# iND83213A register map
Vendor: Indiemicro; Series: Rugby; File version: 1.0
CPU: CM0 r0p1, selectable endian, no MPU, no FPU, 4 interrupt priority bits
Registers are 32-bit, read-write, no defined reset value unless marked. A register's access mark holds for its fields unless they carry their own. Offsets are from the block's base; [hi:lo] are bit positions.

## PMUAPRE5V — Power Management Unit of 5V domain
Base 0x50015000; register names take the prefix PMUAPRE5V_
0x00 RETAIN0 — Retained data 0
  [7:0] RETAIN0 — Firmware scratch register 0. Only reset at power-on (e.g contents retained in Hibernate mode and retained despite any hard or soft resets)
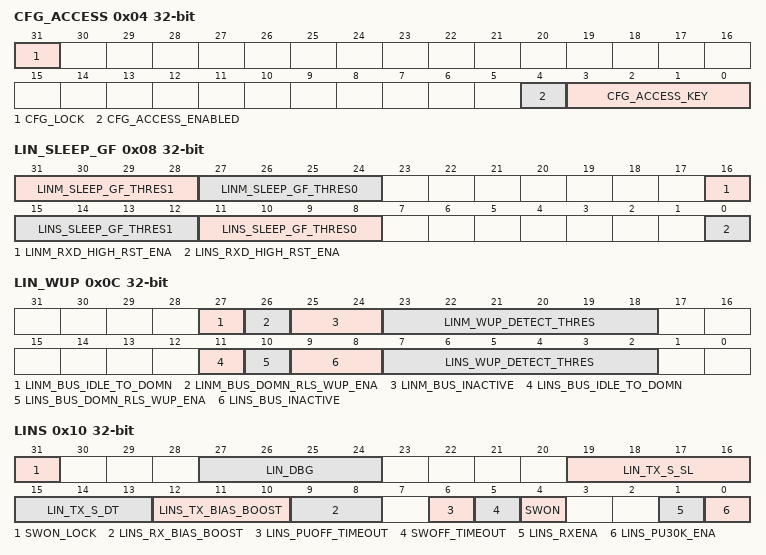
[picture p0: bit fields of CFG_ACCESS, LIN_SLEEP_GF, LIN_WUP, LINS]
0x04 CFG_ACCESS — 5V domain's configuration regs access
  [31] CFG_LOCK — Set Only bit. Write 1 to this bit to lock CFG_CODE bits.
  [4] CFG_ACCESS_ENABLED ro — A status flag that is set when 5V domain's configuration regs access is enabled
  [3:0] CFG_ACCESS_KEY — Write the value 0xB to this register to enable 'trim access' (which allows write access to various trim settings and production test options). Write any other value to disable trim access.
0x08 LIN_SLEEP_GF — LINS Glitch Filter Configuration in active mode.
  [31:28] LINM_SLEEP_GF_THRES1 — LINM RXD glitch filter threshold for 0 to 1, detect '1' width of (T_clk_lf*resetvalue = 4us*3 = 12[us]
  [27:24] LINM_SLEEP_GF_THRES0 — LINM RXD glitch filter threshold for 1 to 0, detect '0' width of (T_clk_lf*resetvalue = 4us*3 = 12[us]
  [16] LINM_RXD_HIGH_RST_ENA — Enable signal that LINs RXD glitch filter at sleep mode is asynchronous reset by high of LINs_RXD.
  [15:12] LINS_SLEEP_GF_THRES1 — LINS RXD glitch filter threshold for 0 to 1, detect '1' width of (T_clk_lf*resetvalue = 4us*3 = 12[us]
  [11:8] LINS_SLEEP_GF_THRES0 — LINS RXD glitch filter threshold for 1 to 0, detect '0' width of (T_clk_lf*resetvalue = 4us*3 = 12[us]
  [0] LINS_RXD_HIGH_RST_ENA — Enable signal that LINs RXD glitch filter at sleep mode is asynchronous reset by high of LINs_RXD.
0x0C LIN_WUP — LIN Wakeup Control,
  [27] LINM_BUS_IDLE_TO_DOMN ro — Dominant Bus Idle Timeout. The bit is set by the lin core if LIN is in hardware mode & the bus is stuck at dominant inactivity state for 4s~10s. Any bus transition will clear this bit. LIN Master's pullup will be disabled when it is set.
  [26] LINM_BUS_DOMN_RLS_WUP_ENA — LIN Master Bus Dominant Release Wakeup Enable. Set to trigger lin wakeup if bus dominant condition is released after BUS_IDLE_TIMEOUT_DOMINANT is detected.
  [25:24] LINM_BUS_INACTIVE — LIN Master Bus Inactivity Time. NOTE: When the chip uses the LINs bus idle detection in pre5v domain(PMU_SFRS->CTRL.PD1V5_ENA_HIBERNATE=0x0), the write operation of this register takes effect by IOCTRLA_SFRS->LIN.UPDATE
  [23:18] LINM_WUP_DETECT_THRES — LIN Master Wakeup Detection Threshold. Threshold setting(LF_CLK_PREDIV clock cycls) of lin wakeup signal. For instace, if target threshold is 150us@LF_CLK_PREDIV=250KHz, WUP_DETECT_THRES = 150/(1000/250)-1. NOTE: When the chip uses the LINs wakeup logic in pre5v domain(PMU_SFRS->CTRL.PD1V5_ENA_HIBERNATE=0x0), the write operation of this register takes effect by IOCTRLA_SFRS->LIN.UPDATE
  [11] LINS_BUS_IDLE_TO_DOMN ro — Dominant Bus Idle Timeout. The bit is set by the lin core if LIN is in hardware mode & the bus is stuck at dominant inactivity state for 4s~10s. Any bus transition will clear this bit. LIN Slave's pullup will be disabled when it is set.
  [10] LINS_BUS_DOMN_RLS_WUP_ENA — LIN Slave Bus Dominant Release Wakeup Enable. Set to trigger lin wakeup if bus dominant condition is released after BUS_IDLE_TIMEOUT_DOMINANT is detected.
  [9:8] LINS_BUS_INACTIVE — LIN Slave Bus Inactivity Time. NOTE: When the chip uses the LINs bus idle detection in pre5v domain(PMU_SFRS->CTRL.PD1V5_ENA_HIBERNATE=0x0), the write operation of this register takes effect by IOCTRLA_SFRS->LIN.UPDATE
  [7:2] LINS_WUP_DETECT_THRES — LIN Slave Wakeup Detection Threshold. Threshold setting(LF_CLK_PREDIV clock cycls) of lin wakeup signal. For instace, if target threshold is 150us@LF_CLK_PREDIV=250KHz, WUP_DETECT_THRES = 150/(1000/250)-1. NOTE: When the chip uses the LINs wakeup logic in pre5v domain(PMU_SFRS->CTRL.PD1V5_ENA_HIBERNATE=0x0), the write operation of this register takes effect by IOCTRLA_SFRS->LIN.UPDATE
0x10 LINS — LIN slave Pin Control.
  [31] SWON_LOCK — SWON Lock Bit.
  [27:24] LIN_DBG — LIN DEBUG. one hot code 0001: select lin_tx_s_duty_ibg1up_tp to gpio2 analog channel 0010: select lin_tx_s_slope_ibg1up_tp to gpio2 analog channel 0100: select lin_tx_m_duty_ibg1up_tp to gpio2 analog channel 1000: select lin_tx_m_slope_ibg1up_tp to gpio2 analog channel
  [19:16] LIN_TX_S_SL — LIN Slave TX driver slew rate select. Slew from 40%*Vbat to 60%*Vbat @Vbat=13V,Cbus=1nF. 0000 -> 1110: 1.07V/us ~ 4.71V/us, step is about 0.26V/us 1111: about 10V/us for fast LIN mode
  [15:13] LIN_TX_S_DT — LIN Slave duty cycle adjust. 0x0: duty cycle = 0.488 0x1: duty cycle = 0.492 0x2: duty cycle = 0.494 0x3: duty cycle = 0.495 0x4: duty cycle = 0.497 0x5: duty cycle = 0.5 0x6: duty cycle = 0.507 0x7: duty cycle = 0.529
  [12:10] LINS_TX_BIAS_BOOST — LIN Slave IO TX Bias select. Select LIN IO TX Pull Down Current. 0x0: ~61 mA 0x1: ~83 mA 0x2: ~105 mA 0x3: ~126 mA
  [9:8] LINS_RX_BIAS_BOOST — adjust rise delay from LIN_IN to Input of LINS Controller. 0x0: 2.323 us 0x1: 1.344 us 0x2: 0.968 us 0x3: 0.767 us
  [6] LINS_PUOFF_TIMEOUT — LINS Pullup Disable in dominant TimeOut condition. Set to disable LINS 30K pullup in case that lin bus is shorted to ground(Bus idle dominant timeout is detected) for saving power. LINS Pullup will be recovered automatically if bus idle dominant timeout is released by any bus activity. Only reset by power-on sequence.
  [5] SWOFF_TIMEOUT — Switch off in dominant TimeOut condition. Set to disconnect lin switch in case that lin bus is shorted to ground(Bus idle dominant timeout is detected) for saving power. LIN Switch will be recovered automatically if bus idle dominant timeout is released by any bus activity. Only reset by power-on sequence.
  [4] SWON — LIN Dual Mode Switch On. Set to enable dual-mode lin switch. Only reset by power-on sequence. This bit can be locked by setting SWON_LOCK.
  [1] LINS_RXENA — LIN receive enable.
  [0] LINS_PU30K_ENA — LIN 30K pullup enable.
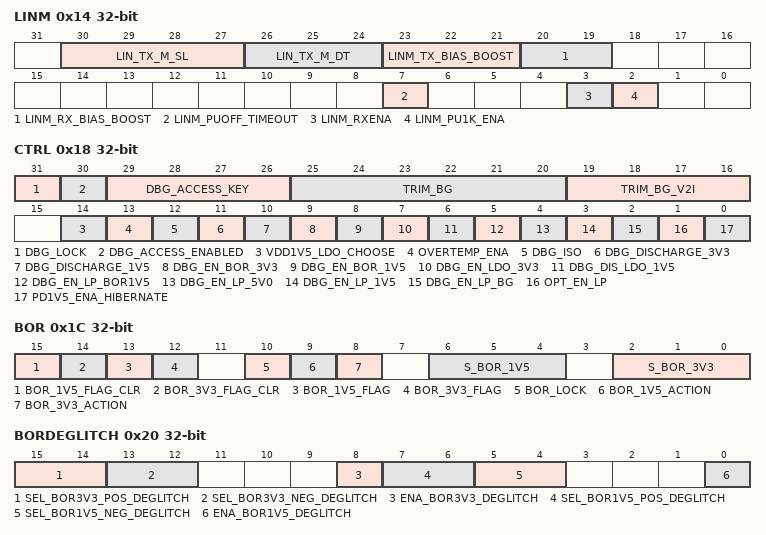
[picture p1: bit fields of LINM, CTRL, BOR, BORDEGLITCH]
0x14 LINM — LIN Master Pin Control.
  [30:27] LIN_TX_M_SL — LIN Master TX driver slew rate select. Slew from 40%*Vbat to 60%*Vbat @Vbat=13V,Cbus=1nF. 0000 -> 1110: 1.07V/us ~ 4.71V/us, step is about 0.26V/us 1111: about 10V/us for fast LIN mode
  [26:24] LIN_TX_M_DT — LIN Master duty cycle adjust. 0x0: duty cycle = 0.488 0x1: duty cycle = 0.492 0x2: duty cycle = 0.494 0x3: duty cycle = 0.495 0x4: duty cycle = 0.497 0x5: duty cycle = 0.5 0x6: duty cycle = 0.507 0x7: duty cycle = 0.529
  [23:21] LINM_TX_BIAS_BOOST — LIN Master IO TX Bias select. Select LIN IO TX Pull Down Current. 0x0: ~61 mA 0x1: ~83 mA 0x2: ~105 mA 0x3: ~126 mA
  [20:19] LINM_RX_BIAS_BOOST — adjust rise delay from LIN_OUT to Input of LINM Controller. 0x0: 2.323 us 0x1: 1.344 us 0x2: 0.968 us 0x3: 0.767 us
  [7] LINM_PUOFF_TIMEOUT — LINM 1K Pullup disable in dominant TimeOut condition. Set to disable LINM 1K pullup in case that lin bus is shorted to ground(Bus idle dominant timeout is detected) for saving power. LINS 1K Pullup will be recovered automatically if bus idle dominant timeout is released by any bus activity. If this bit is set & SWON = 1, LINM's 30K pullup will be enabled for preventing bus floating. Only reset by power-on sequence.
  [3] LINM_RXENA — LIN receive enable.
  [2] LINM_PU1K_ENA — LIN 1K pullup enable.
0x18 CTRL — PMU Debug Control.
  [31] DBG_LOCK — Set Only bit. Set this bit to lock DBG_CODE bits.
  [30] DBG_ACCESS_ENABLED ro — A status flag that is set when debug access is enabled
  [29:26] DBG_ACCESS_KEY — Write the value 0x5 to this register to enable debug options. Write any other value to disable the debug options.
  [25:20] TRIM_BG — Trim the BG core 1.21415V output voltage (1) The voltage range before trimming is 1.16797V ~ 1.26337V. (2) The trim ratio 1/1.4811. (3) The voltage is 1.21455V while TRIM_BG == 0x0. at PMU debug mode
  [19:16] TRIM_BG_V2I — Trim the BG V2I which output the buffered reference voltage.
  [14] VDD1V5_LDO_CHOOSE — 1.5V LDO Mode selection. NOTE: This register is not used by Analog PMU 0x0: choose Capless LDO 0x1: choose Caps LDO
  [13] OVERTEMP_ENA — OverTemp Monitor Enable bit.
  [12] DBG_ISO — NOTE:Don't use. Debug Contrl of isolation of domain 1V5 to domain PRE5V at PMU debug mode.
  [11] DBG_DISCHARGE_3V3 — 3V3 LDO Debug Mode: a. Set '0' to test 3V3-LDO function; b. Set '1' to test 3V3-LDO Discharge Circuit.
  [10] DBG_DISCHARGE_1V5 — 1V5 LDO Debug Mode: a. Set '0' to test 1V5-LDO function; b. Set '1' to test 1V5-LDO Discharge Circuit.
  [9] DBG_EN_BOR_3V3 — Debug Contrl of dis_bor_3v3 at PMU debug mode.
  [8] DBG_EN_BOR_1V5 — Debug Contrl of dis_bor_1v5 at PMU debug mode.
  [7] DBG_EN_LDO_3V3 — NOTE:Don't use.Debug Contrl of en_ldo_3v3 at PMU debug mode.
  [6] DBG_DIS_LDO_1V5 — Debug Contrl of dis_ldo_1v5 at PMU debug mode.(Not Use)
  [5] DBG_EN_LP_BOR1V5 — Set to enable of low power mode for BOR1V5 at PMU debug mode.
  [4] DBG_EN_LP_5V0 — Set to enable of low power mode for LDO5V0 at PMU debug mode.
  [3] DBG_EN_LP_1V5 — Set to enable of low power mode for LDO1V5 at PMU debug mode.
  [2] DBG_EN_LP_BG — Set to enable of low power mode for BG_TOP at PMU debug mode.
  [1] OPT_EN_LP — Set to enable of low power mode for BG_TOP at Deepsleep Mode.
  [0] PD1V5_ENA_HIBERNATE — enable of 1V5 Power Domain at Hibernate mode. set to enable the 1V5 Power Domain at Hibernate mode, this mode is defined as DEEPSLEEP mode.
0x1C BOR — BOR configuration
  [15] BOR_1V5_FLAG_CLR wo — BOR 1v5 clear. Set to clear the 1.5V brownout detected flag
  [14] BOR_3V3_FLAG_CLR wo — BOR 3v3 clear. Set to clear the 3.3V brownout detected flag
  [13] BOR_1V5_FLAG ro — BOR 1v5 flag. Set by the hardware when a brownout of the 1.5V supply is detected.
  [12] BOR_3V3_FLAG ro — BOR 3v3 flag. Set by the hardware when a brownout of the 3.3V supply is detected.
  [10] BOR_LOCK — Set Only bit. Set this bit to lock BOR_ACTION & S_BOR bits.
  [9] BOR_1V5_ACTION — BOR 1v5 action. Defines the consequences of brown-out condition on the 1v5 supply being detected by the hardware. NOTE: The write operation will be locked by BOR_SFRS->BOR_LOCK 0x1: IRQ generated 0x0: Hard reset generated
  [8] BOR_3V3_ACTION — BOR 3v3 action. Defines the consequences of brown-out condition on the 3v3 supply being detected by the hardware. NOTE: The write operation will be locked by BOR_SFRS->BOR_LOCK 0x1: IRQ generated 0x0: Hard reset generated
  [6:4] S_BOR_1V5 — BOR 1v5 threshold. Select the BOR threshold voltage level for the 1v5 regulator. Following typical value can be used as reference: NOTE: The write operation will be locked by BOR_SFRS->BOR_LOCK 0x0: Vr: 1.135 V, Vf: 1.055 V, 0x1: Vr: 1.165 V, Vf: 1.095 V, 0x2: Vr: 1.215 V, Vf: 1.135 V, 0x3: Vr: 1.255 V, Vf: 1.175 V, 0x4: Vr: 1.305 V, Vf: 1.215 V, 0x5: Vr: 1.355 V, Vf: 1.265 V(default), 0x6: Vr: 1.405 V, Vf: 1.315 V, 0x7: Vr: 1.465 V, Vf: 1.375 V,
  [2:0] S_BOR_3V3 — BOR 3v3 threshold. Select the BOR threshold voltage level for the 3v3 regulator, Following typical value can be used as reference: NOTE: The write operation will be locked by BOR_SFRS->BOR_LOCK 0x0: Vr: 2.223 V, Vf: 2.765 V, 0x1: Vr: 2.288 V, Vf: 2.825 V, 0x2: Vr: 2.358 V, Vf: 2.895 V, 0x3: Vr: 2.428 V, Vf: 2.975 V, 0x4: Vr: 2.503 V, Vf: 3.055 V(default), 0x5: Vr: 2.583 V, Vf: 3.135 V, 0x6: Vr: 2.668 V, Vf: 3.225 V, 0x7: Vr: 2.763 V, Vf: 3.315 V,
0x20 BORDEGLITCH
  [15:14] SEL_BOR3V3_POS_DEGLITCH — select the deglitch width of BOR3V3 posedge. 0x0: 16us Selected 0x1: 32us Selected 0x2: 64us Selected 0x3: 128us Selected
  [13:12] SEL_BOR3V3_NEG_DEGLITCH — select the deglitch width of BOR3V3 negedge. 0x0: 16us Selected 0x1: 32us Selected 0x2: 64us Selected 0x3: 128us Selected
  [8] ENA_BOR3V3_DEGLITCH — enable of BOR3V3 deglitch.
  [7:6] SEL_BOR1V5_POS_DEGLITCH — select the deglitch width of BOR1V5 posedge. 0x0: 16us Selected 0x1: 32us Selected 0x2: 64us Selected 0x3: 128us Selected
  [5:4] SEL_BOR1V5_NEG_DEGLITCH — select the deglitch width of BOR1V5 negedge. 0x0: 16us Selected 0x1: 32us Selected 0x2: 64us Selected 0x3: 128us Selected
  [0] ENA_BOR1V5_DEGLITCH — enable of BOR1V5 deglitch.
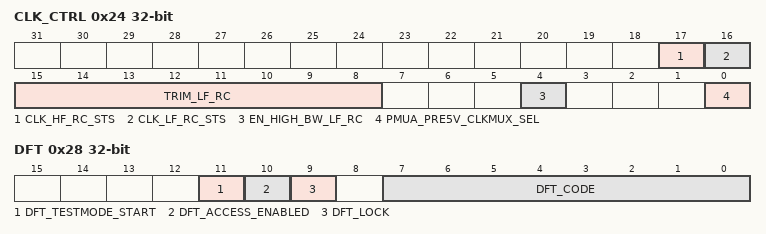
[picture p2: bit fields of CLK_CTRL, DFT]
0x24 CLK_CTRL — Clock controls for 5V(always on) domain.
  [17] CLK_HF_RC_STS ro — Fast oscillator status. Will be high when High Frequency oscillator is enabled
  [16] CLK_LF_RC_STS ro — Slow oscillator status. Will be high when the Low Frequency oscillator is selected
  [15:8] TRIM_LF_RC — LF RC oscillator trim. Following value only used as a reference:(the trim freq is non-linear) 0x0: freq(250k)=141.1Khz 0xa2: freq(250k)=250.0Khz 0xa4: freq(250k)=256.0Khz 0xff: freq(250k)=441.7Khz
  [4] EN_HIGH_BW_LF_RC — set to enable to increase internal comparator bandwidth
  [0] PMUA_PRE5V_CLKMUX_SEL — 5V domain Clock select. Used to switch between the fast and slow 5v domain clocks 0x0: Slow clock 0x1: Fast clock
0x28 DFT
  [11] DFT_TESTMODE_START wo — Puts the ASIC into DFT testmode. Once the start bit is set, the I/O configuration will switch from Application mode to DFT Test Mode. The General Purpose I/Os will be configured as a JTAG interface. Once Test Mode is enabled, the ASIC will be boundary terminated and the processor will lose the ability to communicate with any ASIC peripherals. A chip power cycle is required to get out of the DFT test mode. Test Mode Enable state.
  [10] DFT_ACCESS_ENABLED ro — A status flag that is set when DFT access is enabled.
  [9] DFT_LOCK — Set Only bit. Write 1 to this bit to lock DFT_CODE config bits.
  [7:0] DFT_CODE wo — Write the value 0x1C to this register to Unlock 'Scan Test Mode'.
